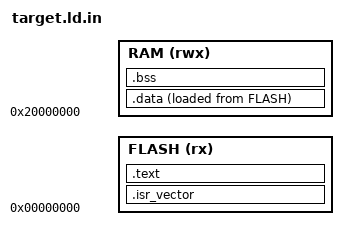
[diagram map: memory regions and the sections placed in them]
/* Linked against the REAL target memory map, so a model that does not fit fails to
   link. The fit test in Table (MCU) is therefore a fact about the binary, not an
   estimate from parameter counts.
     nRF52840 : 1024K flash / 256K RAM   (Cortex-M4F)
     STM32H743: 2048K flash / 1024K RAM  (Cortex-M7)  */
MEMORY
{
  FLASH (rx)  : ORIGIN = 0x00000000, LENGTH = @FLASH_KB@K
  RAM   (rwx) : ORIGIN = 0x20000000, LENGTH = @RAM_KB@K
}

_estack = ORIGIN(RAM) + LENGTH(RAM);

SECTIONS
{
  .isr_vector : { KEEP(*(.isr_vector)) } > FLASH
  .text   : { *(.text*) *(.rodata*) . = ALIGN(4); } > FLASH
  _sidata = LOADADDR(.data);
  .data   : { . = ALIGN(4); _sdata = .; *(.data*) . = ALIGN(4); _edata = .; } > RAM AT> FLASH
  .bss    : { . = ALIGN(4); _sbss = .; *(.bss*) *(COMMON) . = ALIGN(4); _ebss = .; } > RAM
}
